# XMC4300 register map
Vendor: Infineon; File version: 0.5.1 (Superset device XMC4800)
CPU: CM4 r2p0, little endian, MPU, FPU, 6 interrupt priority bits
Registers are 32-bit, read-write, reset 0x0 unless marked. A register's access mark holds for its fields unless they carry their own. Offsets are from the block's base; [hi:lo] are bit positions; {n}, {i} and the like mark numbered series; 'fields as' and 'values as' point back to an identical list.

## ECAT0 — EtherCAT 0
Base 0x54010000
0x00 TYPE 8-bit ro reset 0x98 — Type of EtherCAT Controller
  [7:0] Type — Type of EtherCAT controller
0x01 REVISION 8-bit ro reset 0x1 — Revision of EtherCAT Controller
  [7:0] Revision — Revision of EtherCAT controller
0x02 BUILD 16-bit ro reset 0x1 — Build Version
  [15:0] BUILD — Actual build of EtherCAT controller
0x04 FMMU_NUM 8-bit ro reset 0x8 — FMMUs Supported
  [7:0] NUM_FMMU — Number of supported FMMU channels (or entities) of the EtherCAT Slave Controller
0x05 SYNC_MANAGER 8-bit ro reset 0x8 — SyncManagers Supported
  [7:0] NUM_SM — Number of supported SyncManager channels (or entities) of the EtherCAT Slave Controller
0x06 RAM_SIZE 8-bit ro reset 0x8
  [7:0] RAM_Size — Process Data RAM size supported by the EtherCAT Slave Controller in KByte
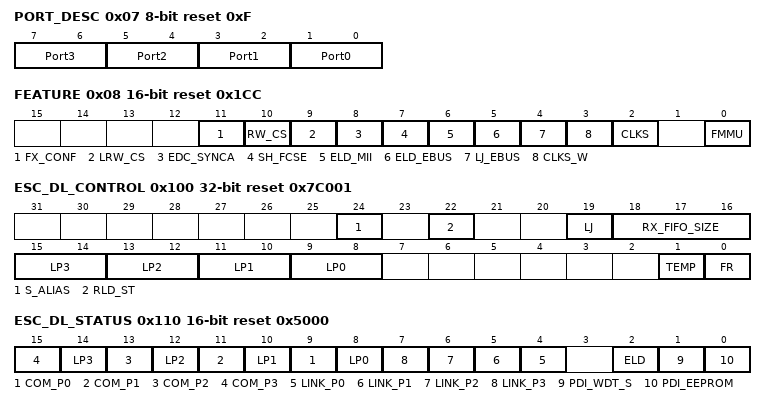
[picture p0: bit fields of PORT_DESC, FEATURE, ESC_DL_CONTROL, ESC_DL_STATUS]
0x07 PORT_DESC 8-bit ro reset 0xF — Port Descriptor
  [all] fields
    0=Not implemented; 1=Not configured (SII EEPROM); 2=EBUS; 3=MII / RMII / RGMII
  [2n+1:2n] Port{n} (n=0..3) — Port Configuration
0x08 FEATURE 16-bit ro reset 0x1CC — ESC Features Supported
  [11] FX_CONF — Fixed FMMU/SyncManager configuration
    0=Variable configuration; 1=Fixed configuration (refer to documentation of supporting ESCs)
  [10] RW_CS — EtherCAT read/write command support (BRW, APRW, FPRW)
    0=Supported; 1=Not supported
  [9] LRW_CS — EtherCAT LRW command support
    0=Supported; 1=Not supported
  [8] EDC_SYNCA — Enhanced DC SYNC Activation
    0=Not available; 1=Available
  [7] SH_FCSE — Separate Handling of FCS Errors
    0=Not supported; 1=Supported, frames with wrong FCS and additional nibble will be counted separately in Forwarded RX Error Counter
  [6] ELD_MII — Enhanced Link Detection MII
    0=Not available; 1=Available
  [5] ELD_EBUS — Enhanced Link Detection EBUS
    0=Not available; 1=Available
  [4] LJ_EBUS — Low Jitter EBUS
    0=Not available, standard jitter; 1=Available, jitter minimized
  [3] CLKS_W — Distributed Clocks (width)
    0=32 bits; 1=64 bits
  [2] CLKS — Distributed Clocks
    0=Not available; 1=Available
  [0] FMMU — FMMU Operation
    0=Bit oriented; 1=Byte oriented
0x10 STATION_ADR 16-bit ro — Configured Station Address
  [15:0] NODE_ADDR — Address used for node addressing (FPxx commands)
0x12 STATION_ALIAS 16-bit — Configured Station Alias
  [15:0] ALIAS_ADDR — Alias Address used for node addressing(FPxx commands)
0x20 WR_REG_ENABLE 8-bit ro — Write Register Enable
  [0] WR_REG_EN — Write register protection enabled
0x21 WR_REG_PROTECT 8-bit ro — Write Register Protection
  [0] WR_REG_P — Write register protection
    0=Protection disabled; 1=Protection enabled
0x30 ESC_WR_ENABLE 8-bit ro — ESC Write Enable
  [0] ESC_WR_PROT — Write protection enabled
0x31 ESC_WR_PROTECT 8-bit ro — ESC Write Protection
  [0] ESC_WR_PROT — Write protect
    0=Protection disabled; 1=Protection enabled
0x40 ESC_RESET_ECAT 8-bit ro (WRITEMode view) — ESC Reset ECAT [WRITE Mode]
  [7:0] RESET_CMD — Reset commands issued by EtherCAt Master
0x40 ESC_RESET_ECAT 8-bit ro (READMode view) — ESC Reset ECAT [READ Mode]
  [1:0] RESET_CMD_STATE — Progress of the reset procedure
    1=after writing 0x52; 2=after writing 0x45 (if 0x52 was written before); 0=default
0x41 ESC_RESET_PDI 8-bit ro (WRITEMode view) — ESC Reset PDI [WRITE Mode]
  [7:0] RESET_CMD — Reset commands issued by XMC4700
0x41 ESC_RESET_PDI 8-bit ro (READMode view) — ESC Reset PDI [READ Mode]
  [1:0] RESET_CMD_STATE — Progress of the reset procedure
    1=after writing 0x52; 2=after writing 0x45 (if 0x52 was written before); 0=default
0x100 ESC_DL_CONTROL ro reset 0x7C001
  [24] S_ALIAS — Station alias
    0=Ignore Station Alias; 1=Alias can be used for all configured address command types (FPRD,FPWR,...)
  [22] RLD_ST — EBUS remote link down signaling time
    0=Default (~660 ms); 1=Reduced (~80 us)
  [19] LJ — EBUS Low Jitter
    0=Normal jitter; 1=Reduced jitter
  [18:16] RX_FIFO_SIZE
    0=-40 ns (-80 ns); 1=-40 ns (-80 ns); 2=-40 ns; 3=-40 ns; 4=no change; 5=no change; 6=no change; 7=default
  [2n+9:2n+8] LP{n} (n=0..3) — Loop Port {n}
    0=Auto; 1=Auto Close; 2=Open; 3=Closed
  [1] TEMP — Temporary use of settings in LP1-LP3
    0=permanent use; 1=use for about 1 second, then revert to previous settings
  [0] FR — Forwarding rule
    0=EtherCAT frames are processed, Non-EtherCAT frames are forwarded without processing; 1=EtherCAT frames are processed, Non- EtherCAT frames are destroyed
0x108 PHYSICAL_RW_OFFSET 16-bit ro — Physical Read/Write Offset
  [15:0] OFFSET — Offset of R/W Commands (FPRW, APRW) between Read address and Write address
0x110 ESC_DL_STATUS 16-bit ro reset 0x5000
  [2n+9] COM_P{n} (n=0..3) — Communication on Port {n}
    0=No stable communication; 1=Communication established
  [2n+8] LP{n} (n=0..3) — Loop Port {n}
    0=Open; 1=Closed
  [n+4] LINK_P{n} (n=0..3) — Physical link on Port {n}
    0=No link; 1=Link detected
  [2] ELD — Enhanced Link detection
    0=Deactivated for all ports; 1=Activated for at least one port
  [1] PDI_WDT_S — PDI Watchdog Status
    0=Watchdog expired; 1=Watchdog reloaded
  [0] PDI_EEPROM — PDI operational/EEPROM loaded correctly
    0=EEPROM not loaded, PDI not operational (no access to Process Data RAM); 1=EEPROM loaded correctly, PDI operational (access to Process Data RAM)
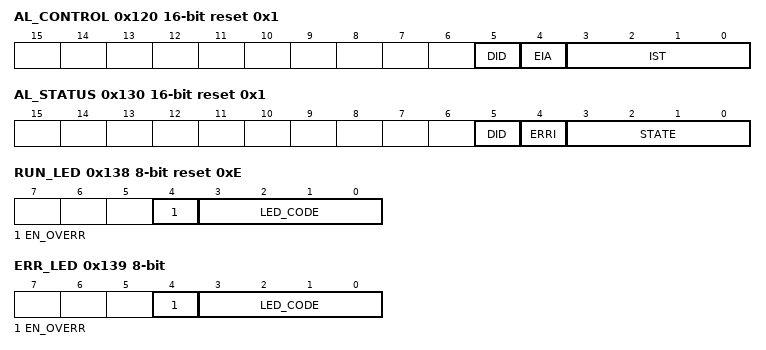
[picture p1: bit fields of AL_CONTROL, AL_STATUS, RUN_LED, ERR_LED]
0x120 AL_CONTROL 16-bit ro reset 0x1
  [5] DID — Device Identification
    0=No request; 1=Device Identification request
  [4] EIA — Error Ind Ack
    0=No Ack of Error Ind in AL status register; 1=Ack of Error Ind in AL status register
  [3:0] IST — Initiate State Transition of the Device StateMachine
    1=Request Init State; 2=Request Pre-Operational State; 3=Request Bootstrap State; 4=Request Safe-Operational State; 8=Request Operational State
0x130 AL_STATUS 16-bit reset 0x1
  [5] DID — Device Identification
    0=Device Identification not valid; 1=Device Identification loaded
  [4] ERRI — Error Ind
    0=Device is in State as requested or Flag cleared by command; 1=Device has not entered requested State or changed State as result of a local action
  [3:0] STATE — Actual State of the Device State Machine
    1=Init State; 2=Pre-Operational State; 3=Bootstrap State; 4=Safe-Operational State; 8=Operational State
0x134 AL_STATUS_CODE 16-bit
  [15:0] AL_S_CODE
0x138 RUN_LED 8-bit reset 0xE — RUN LED Override
  [4] EN_OVERR — Enable Override
    0=Override disable; 1=Override enable
  [3:0] LED_CODE
    0=OFF - Init State; 1=Flash - SafeOp); 13=Blinking - PreOp; 14=Flickering - Bootstrap; 15=On - Operational
0x139 ERR_LED 8-bit — RUN ERR Override
  [4] EN_OVERR — Enable Override
    0=Override disable; 1=Override enable
  [3:0] LED_CODE
    0=OFF; 13=Blinking; 14=Flickering; 15=On
0x140 PDI_CONTROL 8-bit ro reset 0x80
  [7:0] PDI — On-chip bus clock
    0=Interface deactivated (no PDI); 128=On-chip Bus
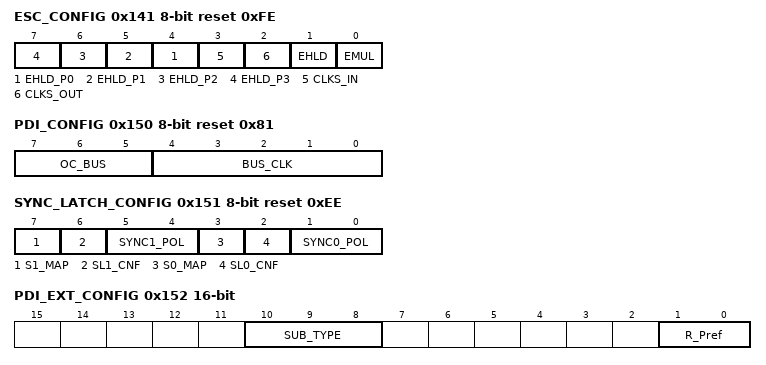
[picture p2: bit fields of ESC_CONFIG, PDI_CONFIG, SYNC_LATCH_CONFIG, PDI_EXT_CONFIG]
0x141 ESC_CONFIG 8-bit ro reset 0xFE — ESC Configuration
  [n+4] EHLD_P{n} (n=0..3) — Enhanced Link port {n}
    0=disabled (if bit 1 = 0); 1=enabled
  [3] CLKS_IN — Distributed Clocks Latch In Unit
    0=disabled (power saving); 1=enabled
  [2] CLKS_OUT — Distributed Clocks SYNC Out Unit
    0=disabled (power saving); 1=enabled
  [1] EHLD — Enhanced Link detection all ports
    0=disabled (if bits [7:4]=0); 1=enabled at all ports (overrides bits [7:4])
  [0] EMUL — Device emulation (control of AL status)
    0=AL status register has to be set by PDI; 1=AL status register will be set to value written to AL control register
0x150 PDI_CONFIG 8-bit ro reset 0x81 — PDI Control
  [7:5] OC_BUS — On-chip bus
    0=Altera Avalon; 1=AXI; 2=Xilinx PLB v4.6; 4=Xilinx OPB
  [4:0] BUS_CLK — On-chip bus clock
    0=asyncronous; 1=values 1-31 is used for synchronous multiplication factor (N*25Mhz)
0x151 SYNC_LATCH_CONFIG 8-bit ro reset 0xEE — Sync/Latch[1:0] PDI Configuration
  [7] S1_MAP — SYNC1 mapped to registerECAT0_AL_EVENT_REQ. ST_S1
    0=Disabled; 1=Enabled
  [6] SL1_CNF — SYNC1/LATCH1 configuration
    0=LATCH1 Input; 1=SYNC1 Output
  [5:4] SYNC1_POL — SYNC1 output driver/polarity
    0=Push-Pull active low; 1=Open Drain (active low); 2=Push-Pull active high; 3=Open Source (active high)
  [3] S0_MAP — SYNC0 mapped to registerECAT0_AL_EVENT_REQ. ST_S0
    0=Disabled; 1=Enabled
  [2] SL0_CNF — SYNC0/LATCH0 configuration
    0=LATCH0 Input; 1=SYNC0 Output
  [1:0] SYNC0_POL — SYNC0 output driver/polarity
    values as SYNC1_POL
0x152 PDI_EXT_CONFIG 16-bit ro — PDI Synchronous Microcontroller extended Configuration
  [10:8] SUB_TYPE — On-chip Sub Type for AXI
    0=AXI3; 1=AXI4; 2=AXI4 Lite
  [1:0] R_Pref — Read Prefetch Size
    0=4 cycles; 1=1 cycle (typical); 2=2 cycles
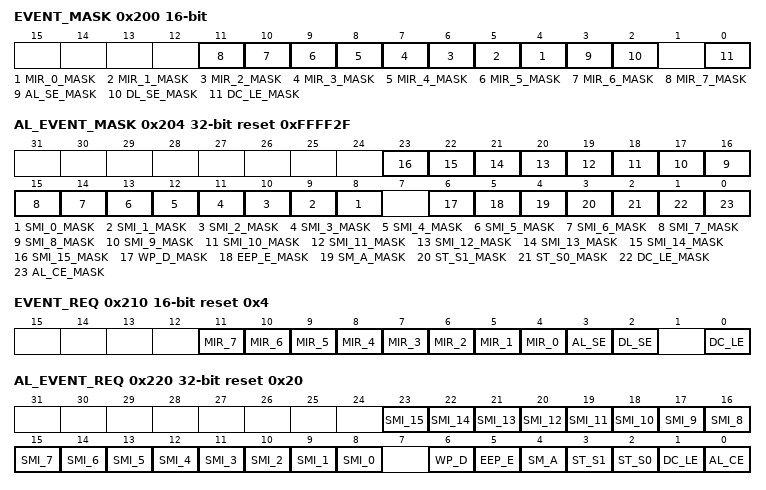
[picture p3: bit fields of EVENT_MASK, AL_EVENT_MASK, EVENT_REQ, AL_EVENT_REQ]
0x200 EVENT_MASK 16-bit ro — ECAT Event Mask
  [all] fields
    0=Corresponding ECAT Event Request register bit is not mapped; 1=Corresponding ECAT Event Request register bit is mapped
  [n+4] MIR_{n}_MASK (n=0..7) — Mirrors values of each SyncManager Status
  [3] AL_SE_MASK — AL Status event
  [2] DL_SE_MASK — DL Status event
  [0] DC_LE_MASK — DC Latch event
0x204 AL_EVENT_MASK reset 0xFFFF2F — PDI AL Event Mask
  [all] fields
    0=Corresponding AL Event Request register bit is not mapped; 1=Corresponding AL Event Request register bit is mapped
  [n+8] SMI_{n}_MASK (n=0..15) — SyncManager interrupt
  [6] WP_D_MASK — Watchdog Process Data
  [5] EEP_E_MASK — EEPROM Emulation
  [4] SM_A_MASK — SyncManager activation register changed
  [3] ST_S1_MASK — State of DC SYNC1
  [2] ST_S0_MASK — State of DC SYNC0
  [1] DC_LE_MASK — DC Latch event
  [0] AL_CE_MASK — AL Control event
0x210 EVENT_REQ 16-bit ro reset 0x4 — ECAT Event Request
  [n+4] MIR_{n} (n=4..7) — Mirrors values of each SyncManager Status
    0=No Sync Channel {n} event; 1=Sync Channel {n} event pending
  [7] MIR_3 — Mirrors values of each SyncManager Status
    0=No Sync Channel 3 event; 1=Sync Channel 3event pending
  [6] MIR_2 — Mirrors values of each SyncManager Status
    0=No Sync Channel 2 event; 1=Sync Channel 2 event pending
  [5] MIR_1 — Mirrors values of each SyncManager Status
    0=No Sync Channel 1 event; 1=Sync Channel 1 event pending
  [4] MIR_0 — Mirrors values of each SyncManager Status
    0=No Sync Channel 0 event; 1=Sync Channel 0 event pending
  [3] AL_SE — AL Status event
    0=No change in AL Status; 1=AL Status change
  [2] DL_SE — DL Status event
    0=No change in DL Status; 1=DL Status change
  [0] DC_LE — DC Latch event
    0=No change on DC Latch Inputs; 1=At least one change on DC Latch Inputs
0x220 AL_EVENT_REQ access per field reset 0x20 — AL Event Request
  [23] SMI_15 ro — SyncManager interrupt
    0=No SyncManager 0 interrupt; 1=SyncManager 0 interrupt pending
  [n+8] SMI_{n} rw (n=2..14) — SyncManager interrupt
    values as SMI_15
  [9] SMI_1 ro — SyncManager interrupt
    values as SMI_15
  [8] SMI_0 ro — SyncManager interrupt
    values as SMI_15
  [6] WP_D ro — Watchdog Process Data
    0=Has not expired; 1=Has expired
  [5] EEP_E ro — EEPROM Emulation
    0=No command pending; 1=EEPROM command pending
  [4] SM_A ro — SyncManager activation register changed
    0=No change in any SyncManager; 1=At least one change on DC Latch Inputs
  [3] ST_S1 ro — State of DC SYNC1
  [2] ST_S0 ro — State of DC SYNC0
  [1] DC_LE ro — DC Latch event
    values as EVENT_REQ.DC_LE
  [0] AL_CE ro — AL Control event
    0=No AL Control Register change; 1=AL Control Register has been written
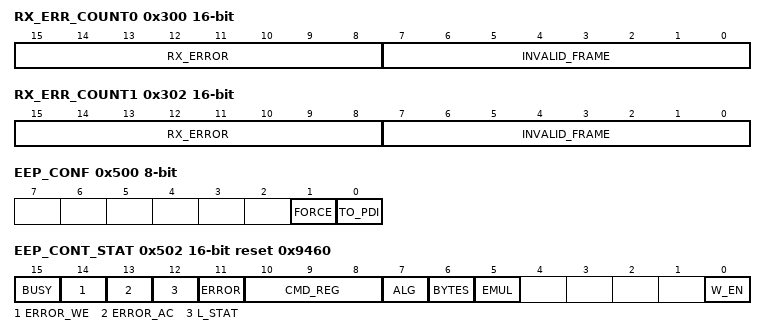
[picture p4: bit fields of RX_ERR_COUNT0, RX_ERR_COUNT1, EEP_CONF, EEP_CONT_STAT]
0x300 RX_ERR_COUNT0 16-bit ro — RX Error Counter Port 0
  [15:8] RX_ERROR — RX Error counter of Port y
  [7:0] INVALID_FRAME — Invalid frame counter of Port y
0x302 RX_ERR_COUNT1 16-bit ro — RX Error Counter Port 1
  fields as RX_ERR_COUNT0
0x308 FWD_RX_ERR_COUNT0 8-bit ro — Forwarded RX Error Counter Port 0
  [7:0] FORW_ERROR — Forwarded error counter of Port y
0x309 FWD_RX_ERR_COUNT1 8-bit ro — Forwarded RX Error Counter Port 1
  [7:0] FORW_ERROR — Forwarded error counter of Port y
0x30C PROC_ERR_COUNT 8-bit ro — ECAT Processing Unit Error Counter
  [7:0] UNIT_ERROR — ECAT Processing Unit error counter
0x30D PDI_ERR_COUNT 8-bit ro — PDI Error Counter
  [7:0] PDI_ERROR_COUNTER
0x310 LOST_LINK_COUNT0 8-bit ro — Lost Link Counter Port 0
  [7:0] LL_COUNTER — Lost Link counter of Port p
0x311 LOST_LINK_COUNT1 8-bit ro — Lost Link Counter Port 1
  [7:0] LL_COUNTER — Lost Link counter of Port p
0x400 WD_DIVIDE 16-bit reset 0x9C2 — Watchdog Divider
  [15:0] WD_DIV — Watchdog divider
0x410 WD_TIME_PDI 16-bit reset 0x3E8 — Watchdog Time PDI
0x420 WD_TIME_PDATA 16-bit reset 0x3E8 — Watchdog Time Process Data
  [15:0] WD_TIME_PD
0x440 WD_STAT_PDATA 16-bit ro — Watchdog Status Process Data
  [0] WD_STAT_PD — Watchdog Status of Process Data
    0=Watchdog Process Data expired; 1=Watchdog Process Data is active or disabled
0x442 WD_COUNT_PDATA 8-bit ro — Watchdog Counter Process Data
  [7:0] WD_COUNTER_PD
0x443 WD_COUNT_PDI 8-bit ro — Watchdog Counter PDI
  [7:0] WD_COUNTER_PDI — Watchdog PDI counter
0x500 EEP_CONF 8-bit ro — EEPROM Configuration
  [1] FORCE — Force ECAT access
    0=Do not change Bit 501.0; 1=Reset Bit 501.0 to 0
  [0] TO_PDI — EEPROM control is offered to PDI
    0=No; 1=Yes (PDI has EEPROM control)
0x501 EEP_STATE 8-bit — EEPROM PDI Access State
  [0] ACCESS — Access to EEPROM
    0=PDI releases EEPROM access; 1=PDI takes EEPROM access (PDI has EEPROM control)
0x502 EEP_CONT_STAT 16-bit access per field reset 0x9460 — EEPROM Control/Status
  [15] BUSY ro
    0=EEPROM Interface is idle; 1=EEPROM Interface is busy
  [14] ERROR_WE ro — Error Write Enable
    0=No error; 1=Write Command without Write enable
  [13] ERROR_AC rw — Error Acknowledge/Command
    0=No error; 1=Missing EEPROM acknowledge or invalid command
  [12] L_STAT ro — EEPROM loading status
    0=EEPROM loaded, device information OK; 1=EEPROM not loaded, device information not available (EEPROM loading in progress or finished with a failure)
  [11] ERROR ro — Checksum Error at in ESC Configuration Area
    0=Checksum OK; 1=Checksum error
  [10:8] CMD_REG rw — Command register
    0=No command/EEPROM idle (clear error bits); 1=Read; 2=Write; 4=Reload
  [7] ALG ro — Selected EEPROM Algorithm
    0=1 address byte (1 KBit - 16 KBit EEPROMs); 1=2 address bytes (32 KBit - 4 MBit EEPROMs)
  [6] BYTES ro — Supported number of EEPROM read bytes
    0=4 Bytes; 1=8 Bytes
  [5] EMUL ro — EEPROM emulation
    0=Normal operation (I2C interface used); 1=PDI emulates EEPROM (I2C not used)
  [0] W_EN ro — ECAT write enable
    0=Write requests are disabled; 1=Write requests are enabled
0x504 EEP_ADR — EEPROM Address
  [31:0] EEPROM_ADDR
    0=First word (= 16 bits); 1=Second word
{0x508+4i} EEP_DATA[{i}] (i=0..1) — EEPROM Read/Write data
  [31:0] EEP_DATA — EEPROM Data
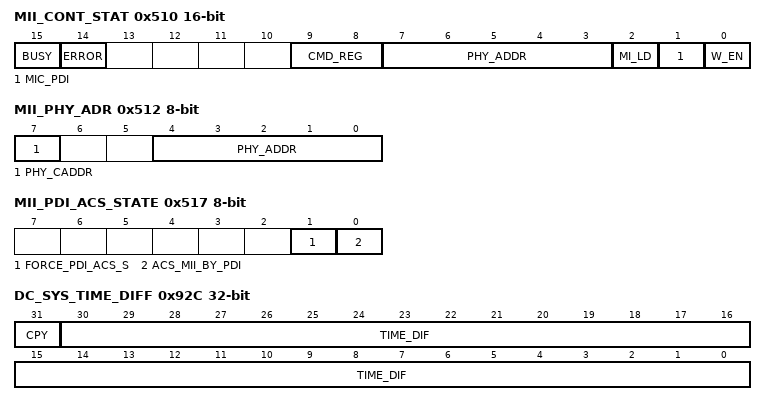
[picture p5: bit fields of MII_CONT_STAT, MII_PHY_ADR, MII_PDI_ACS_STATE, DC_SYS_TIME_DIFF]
0x510 MII_CONT_STAT 16-bit access per field reset not defined — MII Management Control/Status
  [15] BUSY ro
    0=MI control state machine is idle; 1=MI control state machine is active
  [14] ERROR ro — Command error
    0=Last Command was successful; 1=Invalid command or write command without Write Enable
  [9:8] CMD_REG rw — Command register
    0=No command/MII idle (clear error bits); 1=Read; 2=Write; 3=Reserved/invalid commands (do not issue)
  [7:3] PHY_ADDR ro — PHY address of port 0
  [2] MI_LD ro — MI link detection
    0=Not available; 1=MI link detection active
  [1] MIC_PDI ro — Management Interface can be controlled by PDI
    0=Only ECAT control; 1=PDI control possible
  [0] W_EN ro — Write enable
    0=Write disabled; 1=Write enabled
0x512 MII_PHY_ADR 8-bit — PHY Address
  [7] PHY_CADDR — Show configured PHY address of port 0-3 in registerECAT0_MII_CONT_STAT[7:3]. Select port x with bits [4:0] of this register (valid values are 0-3)
    0=Show address of port 0 (offset); 1=Show individual address of port x
  [4:0] PHY_ADDR — PHY Address
0x513 MII_PHY_REG_ADR 8-bit — PHY Register Address
  [4:0] PHY_REG_ADDR — Address of PHY Register that shall beread/written
0x514 MII_PHY_DATA 16-bit — PHY Data
  [15:0] PHY_RW_DATA — PHY Read/Write Data
0x516 MII_ECAT_ACS_STATE 8-bit ro
  [0] EN_ACS_MII_BY_PDI — Access to MII management
    0=ECAT enables PDI takeover of MII management control; 1=ECAT claims exclusive access to MII management
0x517 MII_PDI_ACS_STATE 8-bit access per field
  [1] FORCE_PDI_ACS_S ro — Force PDI Access State by ECAT master
    0=no change; 1=Reset Bit ACS_MII_BY_PDI
  [0] ACS_MII_BY_PDI rw — Access to MII management
    0=ECAT has access to MII managment; 1=PDI has access to MII managment
0x900 DC_RCV_TIME_PORT0 ro reset not defined — Receive Time Port 0
  [31:0] LOCAL_TIME_P0 — Write by EtherCAT master
0x904 DC_RCV_TIME_PORT1 ro reset not defined — Receive Time Port 1
  [31:0] LOCAL_TIME_P1 — Local time of the beginning of a frame
{0x910+4i} DC_SYS_TIME[{i}] (i=0..1) ro (READMode view) — System Time read access
  [31:0] READ_ACCESS
0x910 DC_SYS_TIME wo (WRITEMode view) — System Time [WRITE Mode]
  [31:0] WRITE_ACCESS
{0x918+4i} RECEIVE_TIME_PU[{i}] (i=0..1) ro reset not defined — Local time of the beginning of a frame
  [31:0] RECEIVE_TIME_PU
{0x920+4i} DC_SYS_TIME_OFFSET[{i}] (i=0..1) — Difference between local time and System Time
  [31:0] DC_SYS_TIME_OFFSET
0x928 DC_SYS_TIME_DELAY — System Time Delay
  [31:0] CLK_DELAY — Delay between Reference Clock and the ESC
0x92C DC_SYS_TIME_DIFF ro — System Time Difference
  [31] CPY — Local copy of System Time
    0=Greater than or equal received System Time; 1=Smaller than received System Time
  [30:0] TIME_DIF — Mean difference between local copy of System Time and received System Time values
0x930 DC_SPEED_COUNT_START 16-bit reset 0x1000 — Speed Counter Start
  [14:0] COUNT_START — Bandwidth for adjustment of local copy of System Time
0x932 DC_SPEED_COUNT_DIFF 16-bit ro — Speed Counter Diff
  [15:0] DEVIATION — Representation of the deviation between local clock period and Reference Clock's clock period
0x934 DC_SYS_TIME_FIL_DEPTH 8-bit reset 0x4 — System Time Difference Filter Depth
  [3:0] FILTER_DEPTH — Filter depth for averaging the received System Time deviation
0x935 DC_SPEED_COUNT_FIL_DEPTH 8-bit reset 0xC — Speed Counter Filter Depth
  [3:0] FILTER_DEPTH — Filter depth for averaging the clock period deviation
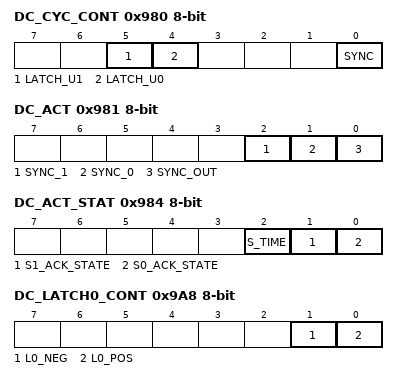
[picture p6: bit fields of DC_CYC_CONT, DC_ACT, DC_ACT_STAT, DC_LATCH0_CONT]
0x980 DC_CYC_CONT 8-bit ro — Cyclic Unit Control
  [all] fields
    0=ECAT controlled; 1=PDI controlled
  [5] LATCH_U1 — Latch In unit 1
  [4] LATCH_U0 — Latch In unit 0
  [0] SYNC — SYNC out unit control
0x981 DC_ACT 8-bit — Activation register
  [2] SYNC_1 — SYNC1 generation
    0=Deactivated; 1=SYNC1 pulse is generated
  [1] SYNC_0 — SYNC0 generation
    0=Deactivated; 1=SYNC0 pulse is generated
  [0] SYNC_OUT — Sync Out Unit activation
    0=Deactivated; 1=Activated
0x982 DC_PULSE_LEN 16-bit ro reset not defined — Pulse Length of SyncSignals
  [15:0] PULS_LENGTH — Pulse length of SyncSignals
    0=Acknowledge mode: SyncSignal will be cleared by reading SYNC[1:0] Status register
0x984 DC_ACT_STAT 8-bit ro — Activation Status
  [2] S_TIME — Start Time Cyclic Operation
    0=Start Time was within near future; 1=Start Time was out of near future (0x0981.6)
  [1] S1_ACK_STATE — SYNC1 activation state
    0=First SYNC1 pulse is not pending; 1=First SYNC1 pulse is pending
  [0] S0_ACK_STATE — SYNC0 activation state
    0=First SYNC0 pulse is not pending; 1=First SYNC0 pulse is pending
0x98E DC_SYNC0_STAT 8-bit ro — SYNC0 Status
  [0] S0_STATE — SYNC0 state for Acknowledge mode
0x98F DC_SYNC1_STAT 8-bit ro — SYNC1 Status
  [0] S1_STATE — SYNC1 state for Acknowledge mode
{0x990+4i} DC_CYC_START_TIME[{i}] (i=0..1) — Start Time Cyclic Operation
  [31:0] DC_CYC_START_TIME
{0x998+4i} DC_NEXT_SYNC1_PULSE[{i}] (i=0..1) ro — System time of next SYNC1 pulse in ns
  [31:0] DC_NEXT_SYNC1_PULSE
0x9A0 DC_SYNC0_CYC_TIME — SYNC0 Cycle Time
  [31:0] TIME_BETWEEN_SYNC0 — Time between two consecutive SYNC0 pulses
    0=Single shot mode, generate only one SYNC0 pulse
0x9A4 DC_SYNC1_CYC_TIME — SYNC1 Cycle Time
  [31:0] TIME_SYNC1_SYNC0 — Time between SYNC1 pulses and SYNC0 pulse
0x9A8 DC_LATCH0_CONT 8-bit — Latch0 Control
  [1] L0_NEG — Latch0 negative edge
    0=Continuous Latch active; 1=Single event (only first event active)
  [0] L0_POS — Latch0 positive edge
    values as L0_NEG
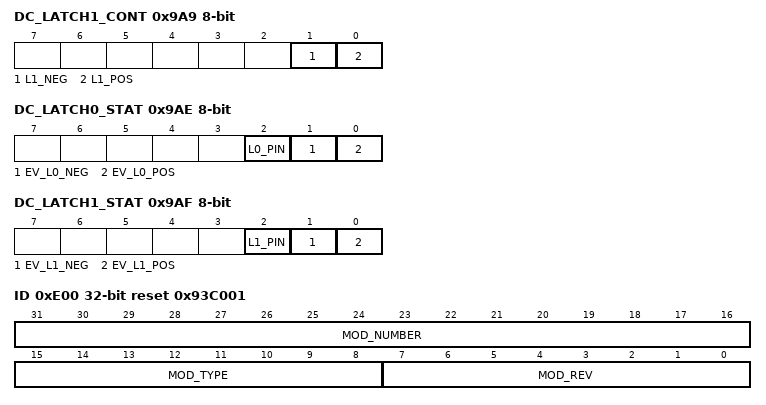
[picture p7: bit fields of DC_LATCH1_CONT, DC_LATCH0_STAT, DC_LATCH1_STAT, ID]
0x9A9 DC_LATCH1_CONT 8-bit — Latch1 Control
  [1] L1_NEG — Latch1 negative edge
    values as DC_LATCH0_CONT.L0_NEG
  [0] L1_POS — Latch1 positive edge
    values as DC_LATCH0_CONT.L0_NEG
0x9AE DC_LATCH0_STAT 8-bit ro reset not defined — Latch0 Status
  [2] L0_PIN — Latch0 pin state
  [1] EV_L0_NEG — Event Latch0 negative edge
    0=Negative edge not detected or continuous mode; 1=Negative edge detected in single event mode only
  [0] EV_L0_POS — Event Latch0 positive edge
    0=Positive edge not detected or continuous mode; 1=Positive edge detected in single event mode only
0x9AF DC_LATCH1_STAT 8-bit ro reset not defined — Latch1 Status
  [2] L1_PIN — Latch1 pin state
  [1] EV_L1_NEG — Event Latch1 negative edge
    values as DC_LATCH0_STAT.EV_L0_NEG
  [0] EV_L1_POS — Event Latch1 positive edge
    values as DC_LATCH0_STAT.EV_L0_POS
{0x9B0+4i} DC_LATCH0_TIME_POS[{i}] (i=0..1) ro — Register captures System time at the positive edge of the Latch0 signal
  [31:0] DC_LATCH0_TIME_POS — Captures System time at the positive edge of the Latch0 signal
{0x9B8+4i} DC_LATCH0_TIME_NEG[{i}] (i=0..1) ro — Register captures System time at the negative edge of the Latch0 signal
  [31:0] DC_LATCH0_TIME_NEG — Captures System time at the negative edge of the Latch0 signal
{0x9C0+4i} DC_LATCH1_TIME_POS[{i}] (i=0..1) ro — Register captures System time at the positive edge of the Latch1 signal
  [31:0] DC_LATCH1_TIME_POS — Captures System time at the positive edge of the Latch1 signal
{0x9C8+4i} DC_LATCH1_TIME_NEG[{i}] (i=0..1) ro — Register captures System time at the negative edge of the Latch1 signal
  [31:0] DC_LATCH1_TIME_NEG — Captures System time at the negative edge of the Latch1 signal
0x9F0 DC_ECAT_CNG_EV_TIME ro — EtherCAT Buffer Change Event Time
  [31:0] ECAT_CNG_EV_TIME — Register captures local time of the beginning of the frame which causes at least one SyncManager to assert an ECAT event
0x9F8 DC_PDI_START_EV_TIME ro — PDI Buffer Start Event Time
  [31:0] PDI_START_EV_TIME — Register captures local time when at least one SyncManager asserts an PDI buffer start event
0x9FC DC_PDI_CNG_EV_TIME ro — PDI Buffer Change Event Time
  [31:0] PDI_CNG_EV_TIME — Register captures local time when at least one SyncManager asserts an PDI buffer change event
0xE00 ID ro reset 0x93C001 — ECAT0 Module ID
  [31:16] MOD_NUMBER — Module Number Value
  [15:8] MOD_TYPE — Module Type
  [7:0] MOD_REV — Module Revision Number
0xE08 STATUS ro — ECAT0 Status
  [0] PARERR — PARITY ERROR
    0=No Error; 1=Parity Error in User or Process RAM
